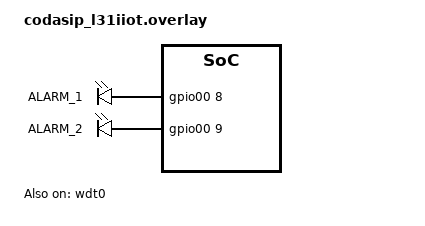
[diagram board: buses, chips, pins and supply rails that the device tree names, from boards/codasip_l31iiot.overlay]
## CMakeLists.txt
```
# SPDX-License-Identifier: Apache-2.0

cmake_minimum_required(VERSION 3.20.0)
find_package(Zephyr REQUIRED HINTS $ENV{ZEPHYR_BASE})
project(policy_mngr)

target_sources(app PRIVATE src/main.c)
```

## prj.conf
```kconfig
CONFIG_LOG=y
CONFIG_LOG_MODE_IMMEDIATE=y
CONFIG_POLICY_MNGR_LOG_LEVEL_DBG=y
CONFIG_POLICY_MNGR=y
```

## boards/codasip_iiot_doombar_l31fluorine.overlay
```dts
/*
 * Copyright (c) 2023 Codasip s.r.o.
 *
 * SPDX-License-Identifier: Apache-2.0
 */

/ {
        aliases {
            alarm1 = &alarm1;
            alarm2 = &alarm2;
            watchdog0 = &wdt0;
        };

        outputs {
                /*  GPIO01 - AUX
                    gpio_in[0]  = SD_CARD_DETECT_N
                    gpio_in[1]  = SD_PWR_EN_N
                    gpio_out[1] = SD_PWR_EN_N
                    gpio_out[2] = SD_20MHZ_CLK_EN

                    gpio_out[3] = ALARM_1 (send alarm to Policy Manager)
                    gpio_out[4] = ALARM_2 (send alarm to Policy Manager)
                    - For more info see: https://codasip.atlassian.net/browse/PLAT-1772
                */

            /* GPIO01 = AUX */
            alarm1: alarm1 {
                gpios = <&gpio01 3 GPIO_ACTIVE_HIGH>;	/* This output connects to Policy Manager Alarm input port 1 */
                label = "ALARM_1";
            };
            alarm2: alarm2 {
                gpios = <&gpio01 4 GPIO_ACTIVE_HIGH>;	/* This output connects to Policy Manager Alarm input port 2 */
                label = "ALARM_2";
            };
        };

};

&wdt0 {
	status = "okay";
};
```

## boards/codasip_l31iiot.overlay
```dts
/*
 * Copyright (c) 2023 Codasip s.r.o.
 *
 * SPDX-License-Identifier: Apache-2.0
 */

/ {
        aliases {
            alarm1 = &alarm1;
            alarm2 = &alarm2;
            watchdog0 = &wdt0;
        };

        soc {
                gpio01: gpio@60310000 {
                    ngpios = <10>;  		/* Number of GPIO pins. 
                               gpio_in[0]  = SD_CARD_DETECT_N
                               gpio_in[1]  = SD_PWR_EN_N
                               gpio_out[1] = SD_PWR_EN_N
                               gpio_out[2] = IRQ 2 (send interrupt request to the PIC)
                               gpio_out[3] = IRQ 3 (send interrupt request to the PIC) 

                        The following is only in the following BitStream for testing: 
                            https://gitlab.codasip.com/platforms/l31-fpga-platform/-/jobs/1166045/artifacts/file/work/l31-dcls-5.0.3-9.4.1-vivado-project-platform-0.10.0.zip
                            
                               gpio_out[8] = Alarm 1 (send alarm to Policy Manager) 
                               gpio_out[9] = Alarm 2 (send alarm to Policy Manager) 
                               
                        For more info see:
                            https://codasip.atlassian.net/browse/PLAT-1536
                        */
                };
        };

        leds {
            /* GPI00 = SWITCH/LED */
            alarm1: alarm1 {
                gpios = <&gpio00 8 GPIO_ACTIVE_HIGH>;	/* This output connects to Policy Manager Alarm input port 1 */
                label = "ALARM_1";
            };
            alarm2: alarm2 {
                gpios = <&gpio00 9 GPIO_ACTIVE_HIGH>;	/* This output connects to Policy Manager Alarm input port 2 */
                label = "ALARM_2";
            };
        };

};

&wdt0 {
	status = "okay";
};
```

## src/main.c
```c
/*
 * Copyright (c) 2023 Codasip s.r.o.
 *
 * SPDX-License-Identifier: Apache-2.0
 */

#include <zephyr/kernel.h>
#include <zephyr/device.h>
#include <zephyr/drivers/gpio.h>
#include <zephyr/drivers/policy_mngr.h>
#include <zephyr/sys/printk.h>
#include <stdbool.h>

#define POLICY_MNGR_ALARM0_L31AS (0)
#define POLICY_MNGR_ALARM1_GPIO3 (1)
#define POLICY_MNGR_ALARM2_GPIO4 (2)

#define IRQ_ALARM_NUM DT_IRQ_BY_IDX(DT_NODELABEL(policy_mngr0), 0, irq)

/* The devicetree node identifiers for "alarm1" & "alarm2" alias. */
#define ALARM1_NODE DT_ALIAS(alarm1)
#define ALARM2_NODE DT_ALIAS(alarm2)

static const struct gpio_dt_spec alarm1 = GPIO_DT_SPEC_GET(ALARM1_NODE, gpios);
static const struct gpio_dt_spec alarm2 = GPIO_DT_SPEC_GET(ALARM2_NODE, gpios);

static void policy_mngr_callback(const struct device *dev, int alarm_id)
{
        printk("Policy Manager Interrupt Callback for alarm_id = %d\n", alarm_id);

        /* Clear the alarm source */
        switch (alarm_id) {
        case 1:
                gpio_pin_set_dt(&alarm1, 0);
                break;

        case 2:
                gpio_pin_set_dt(&alarm2, 0);
                break;

        default:
                break;
        }
}

int main(void)
{
        const struct device *const policy_mngr_dev = DEVICE_DT_GET(DT_NODELABEL(policy_mngr0));

        printk("Policy Manager sample application\n");
        printk("NOTE: THIS TEST CODE ONLY WORKS IF AUX GPIO01 (Aux) 3 & 4 CONNECTIONS TO THE "
               "POLICY MANAGER ALARMS 1 & 2 HAVE BEEN CONNECTED IN THE RTL\n");

        if (!device_is_ready(policy_mngr_dev)) {
                printk("%s: device not ready.\n", policy_mngr_dev->name);
                return 0;
        }

        if (policy_mngr_setup(policy_mngr_dev, policy_mngr_callback) != 0) {
                printk("%s: Error setting device up.\n", policy_mngr_dev->name);
                return 0;
        }

        if (policy_mngr_set_alarm(policy_mngr_dev, POLICY_MNGR_ALARM0_L31AS,
                                  POLICY_MNGR_ALARM_ACTION_INT_CALLBACK) != 0) {
                printk("%s: Error setting alarm id %d\n", policy_mngr_dev->name,
                       POLICY_MNGR_ALARM0_L31AS);
                return 0;
        }

        printk("alarm1 & alarm2 not configured in policy manager yet - should do nothing\n");

        printk("Firing alarm1 \n");
        gpio_pin_set_dt(&alarm1, 1);

        k_sleep(K_MSEC(3000));

        printk("Firing alarm2 \n");
        gpio_pin_set_dt(&alarm2, 1);

        k_sleep(K_MSEC(3000));

        printk("Setting Alarm1 for Int Callback\n");

        if (policy_mngr_set_alarm(policy_mngr_dev, POLICY_MNGR_ALARM1_GPIO3,
                                  POLICY_MNGR_ALARM_ACTION_INT_CALLBACK) != 0) {
                printk("%s: Error setting alarm id %d\n", policy_mngr_dev->name,
                       POLICY_MNGR_ALARM1_GPIO3);
                return 0;
        }

        k_sleep(K_MSEC(3000));

        printk("Firing alarm1 \n");
        gpio_pin_set_dt(&alarm1, 1);

        k_sleep(K_MSEC(3000));

        printk("Setting Alarm2 for Int Callback\n");

        if (policy_mngr_set_alarm(policy_mngr_dev, POLICY_MNGR_ALARM2_GPIO4,
                                  POLICY_MNGR_ALARM_ACTION_INT_CALLBACK) != 0) {
                printk("%s: Error setting alarm id %d\n", policy_mngr_dev->name,
                       POLICY_MNGR_ALARM2_GPIO4);
                return 0;
        }

        k_sleep(K_MSEC(3000));

        printk("Firing alarm2 \n");
        gpio_pin_set_dt(&alarm2, 1);

        k_sleep(K_MSEC(3000));

        printk("Setting Alarm2 for RESET\n");

        if (policy_mngr_set_alarm(policy_mngr_dev, POLICY_MNGR_ALARM2_GPIO4,
                                  POLICY_MNGR_ALARM_ACTION_RESET) != 0) {
                printk("%s: Error setting alarm id %d\n", policy_mngr_dev->name,
                       POLICY_MNGR_ALARM2_GPIO4);
                return 0;
        }

        k_sleep(K_MSEC(3000));

        printk("Firing alarm2\n");

        k_sleep(K_MSEC(1000));

        gpio_pin_set_dt(&alarm2, 1);

        printk("Alarm2 fired - Reset should have happened and you should not see this message\n");

        /* Waiting for the SoC reset. */
        printk("Waiting for reset...\n");
        while (1) {
                k_yield();
        }

        return 0;
}
```
